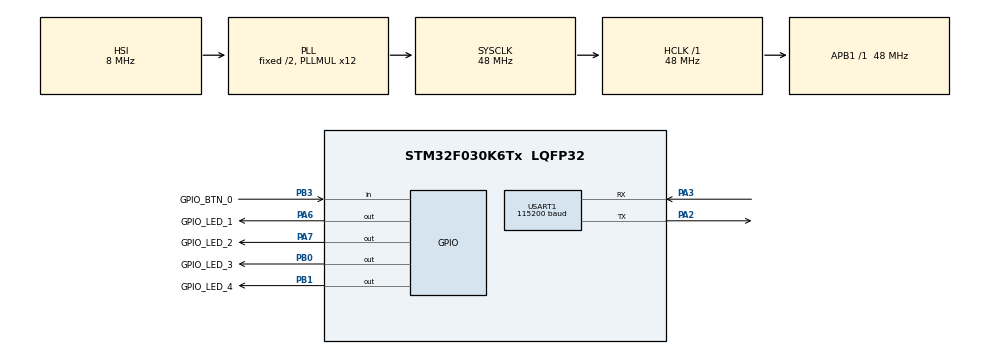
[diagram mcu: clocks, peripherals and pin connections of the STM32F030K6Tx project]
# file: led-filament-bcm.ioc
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Mcu.Family=STM32F0
Mcu.Name=STM32F030K6Tx
Mcu.Package=LQFP32
NVIC.USART1_IRQn=true\:0\:0\:false\:false\:false\:true\:true\:true
PA13.Mode=Serial_Wire
PA13.Signal=SYS_SWDIO
PA14.Mode=Serial_Wire
PA14.Signal=SYS_SWCLK
PA2.Mode=Asynchronous
PA2.Signal=USART1_TX
PA3.Mode=Asynchronous
PA3.Signal=USART1_RX
PA6.GPIO_Label=GPIO_LED_1
PA6.GPIO_Speed=GPIO_SPEED_FREQ_HIGH
PA6.PinState=GPIO_PIN_RESET
PA6.Signal=GPIO_Output
PA7.GPIO_Label=GPIO_LED_2
PA7.GPIO_Speed=GPIO_SPEED_FREQ_HIGH
PA7.Signal=GPIO_Output
PB0.GPIO_Label=GPIO_LED_3
PB0.GPIO_Speed=GPIO_SPEED_FREQ_HIGH
PB0.Signal=GPIO_Output
PB1.GPIO_Label=GPIO_LED_4
PB1.GPIO_Speed=GPIO_SPEED_FREQ_HIGH
PB1.Signal=GPIO_Output
PB3.GPIO_Label=GPIO_BTN_0
PB3.Signal=GPIO_Input
ProjectManager.HeapSize=0x200
ProjectManager.StackSize=0x400
ProjectManager.TargetToolchain=STM32CubeIDE
RCC.AHBFreq_Value=48000000
RCC.APB1Freq_Value=48000000
RCC.APB1TimFreq_Value=48000000
RCC.HCLKFreq_Value=48000000
RCC.PLLMUL=RCC_PLL_MUL12
RCC.SYSCLKFreq_VALUE=48000000
RCC.SYSCLKSource=RCC_SYSCLKSOURCE_PLLCLK
USART1.BaudRate=115200
USART1.VirtualMode-Asynchronous=VM_ASYNC
board=custom

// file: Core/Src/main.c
/* USER CODE BEGIN Header */
/**
  ******************************************************************************
  * @file           : main.c
  * @brief          : Main program body
  ******************************************************************************
  * @attention
  *
  * Copyright (c) 2023 STMicroelectronics.
  * All rights reserved.
  *
  * This software is licensed under terms that can be found in the LICENSE file
  * in the root directory of this software component.
  * If no LICENSE file comes with this software, it is provided AS-IS.
  *
  ******************************************************************************
  */
/* USER CODE END Header */
#include "main.h"
#include "usart.h"
#include "gpio.h"

/* USER CODE BEGIN Includes */
#include "application/app.h"
#include "middleware/bcmled.h"
#include "middleware/uart.h"
/* USER CODE END Includes */

void SystemClock_Config(void);

int main(void)
{

  /* MCU Configuration--------------------------------------------------------*/

  /* Reset of all peripherals, Initializes the Flash interface and the Systick. */
  HAL_Init();

  /* Configure the system clock */
  SystemClock_Config();

  /* Initialize all configured peripherals */
  MX_GPIO_Init();
  MX_USART1_UART_Init();
  /* USER CODE BEGIN 2 */
  BCMLED_init();
  UART_init();
  /* USER CODE END 2 */

  /* Infinite loop */
  while (1)
  {

    /* USER CODE BEGIN 3 */

      APP_task();
      BCMLED_task();
  }
  /* USER CODE END 3 */
}

void SystemClock_Config(void)
{
  RCC_OscInitTypeDef RCC_OscInitStruct = {0};
  RCC_ClkInitTypeDef RCC_ClkInitStruct = {0};
  RCC_PeriphCLKInitTypeDef PeriphClkInit = {0};

  /** Initializes the RCC Oscillators according to the specified parameters
  * in the RCC_OscInitTypeDef structure.
  */
  RCC_OscInitStruct.OscillatorType = RCC_OSCILLATORTYPE_HSI;
  RCC_OscInitStruct.HSIState = RCC_HSI_ON;
  RCC_OscInitStruct.HSICalibrationValue = RCC_HSICALIBRATION_DEFAULT;
  RCC_OscInitStruct.PLL.PLLState = RCC_PLL_ON;
  RCC_OscInitStruct.PLL.PLLSource = RCC_PLLSOURCE_HSI;
  RCC_OscInitStruct.PLL.PLLMUL = RCC_PLL_MUL12;
  RCC_OscInitStruct.PLL.PREDIV = RCC_PREDIV_DIV1;
  if (HAL_RCC_OscConfig(&RCC_OscInitStruct) != HAL_OK)
  {
    Error_Handler();
  }

  /** Initializes the CPU, AHB and APB buses clocks
  */
  RCC_ClkInitStruct.ClockType = RCC_CLOCKTYPE_HCLK|RCC_CLOCKTYPE_SYSCLK
                              |RCC_CLOCKTYPE_PCLK1;
  RCC_ClkInitStruct.SYSCLKSource = RCC_SYSCLKSOURCE_PLLCLK;
  RCC_ClkInitStruct.AHBCLKDivider = RCC_SYSCLK_DIV1;
  RCC_ClkInitStruct.APB1CLKDivider = RCC_HCLK_DIV1;

  if (HAL_RCC_ClockConfig(&RCC_ClkInitStruct, FLASH_LATENCY_1) != HAL_OK)
  {
    Error_Handler();
  }
  PeriphClkInit.PeriphClockSelection = RCC_PERIPHCLK_USART1;
  PeriphClkInit.Usart1ClockSelection = RCC_USART1CLKSOURCE_PCLK1;
  if (HAL_RCCEx_PeriphCLKConfig(&PeriphClkInit) != HAL_OK)
  {
    Error_Handler();
  }
}

void Error_Handler(void)
{
  __disable_irq();
  while (1)
  {
  }
}
